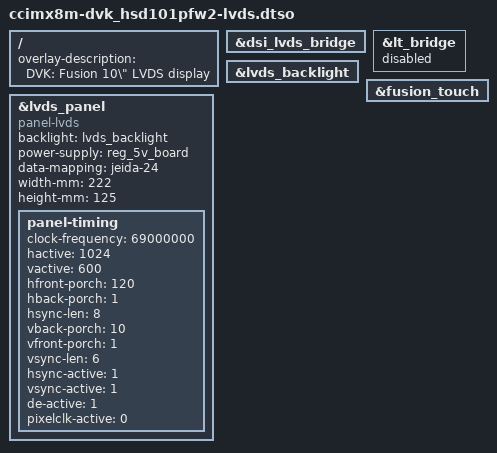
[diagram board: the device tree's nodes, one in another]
/*
 * Copyright 2020-2021 Digi International Inc.
 *
 * Permission to use, copy, modify, and/or distribute this software for any
 * purpose with or without fee is hereby granted, provided that the above
 * copyright notice and this permission notice appear in all copies.
 * THE SOFTWARE IS PROVIDED "AS IS" AND THE AUTHOR DISCLAIMS ALL WARRANTIES
 * WITH REGARD TO THIS SOFTWARE INCLUDING ALL IMPLIED WARRANTIES OF
 * MERCHANTABILITY AND FITNESS. IN NO EVENT SHALL THE AUTHOR BE LIABLE FOR
 * ANY SPECIAL, DIRECT, INDIRECT, OR CONSEQUENTIAL DAMAGES OR ANY DAMAGES
 * WHATSOEVER RESULTING FROM LOSS OF USE, DATA OR PROFITS, WHETHER IN AN
 * ACTION OF CONTRACT, NEGLIGENCE OR OTHER TORTIOUS ACTION, ARISING OUT OF
 * OR IN CONNECTION WITH THE USE OR PERFORMANCE OF THIS SOFTWARE.
 */

/dts-v1/;
/plugin/;

/ {
	fragment@0 {
		target-path = "/";
		__overlay__ {
			overlay-description = "DVK: Fusion 10\" LVDS display";
		};
	};

	/* Enable the LVDS bridge */
	fragment@1 {
		target = <&dsi_lvds_bridge>;
		__overlay__ {
			status = "okay";
		};
	};

	/* Disable the HDMI bridge */
	fragment@2 {
		target = <&lt_bridge>;
		__overlay__ {
			status = "disabled";
		};
	};

	/* Enable lvds_backlight */
	fragment@3 {
		target = <&lvds_backlight>;
		__overlay__ {
			status = "okay";
		};
	};

	/* Enable Fusion touch */
	fragment@4 {
		target = <&fusion_touch>;
		__overlay__ {
			status = "okay";
		};
	};

	/* Enable lvds_panel */
	fragment@5 {
		target = <&lvds_panel>;
		__overlay__ {
		compatible = "panel-lvds";
			status = "okay";
			backlight = <&lvds_backlight>;
			power-supply = <&reg_5v_board>;
			data-mapping = "jeida-24";
			width-mm = <222>;
			height-mm = <125>;

			/* Fusion 10" F10A-0102 */
			panel-timing {
				clock-frequency = <69000000>;
				hactive = <1024>;
				vactive = <600>;
				hfront-porch = <120>;
				hback-porch = <1>;
				hsync-len = <8>;
				vback-porch = <10>;
				vfront-porch = <1>;
				vsync-len = <6>;
				hsync-active = <1>;
				vsync-active = <1>;
				de-active = <1>;
				pixelclk-active = <0>;
			};
		};
	};
};
